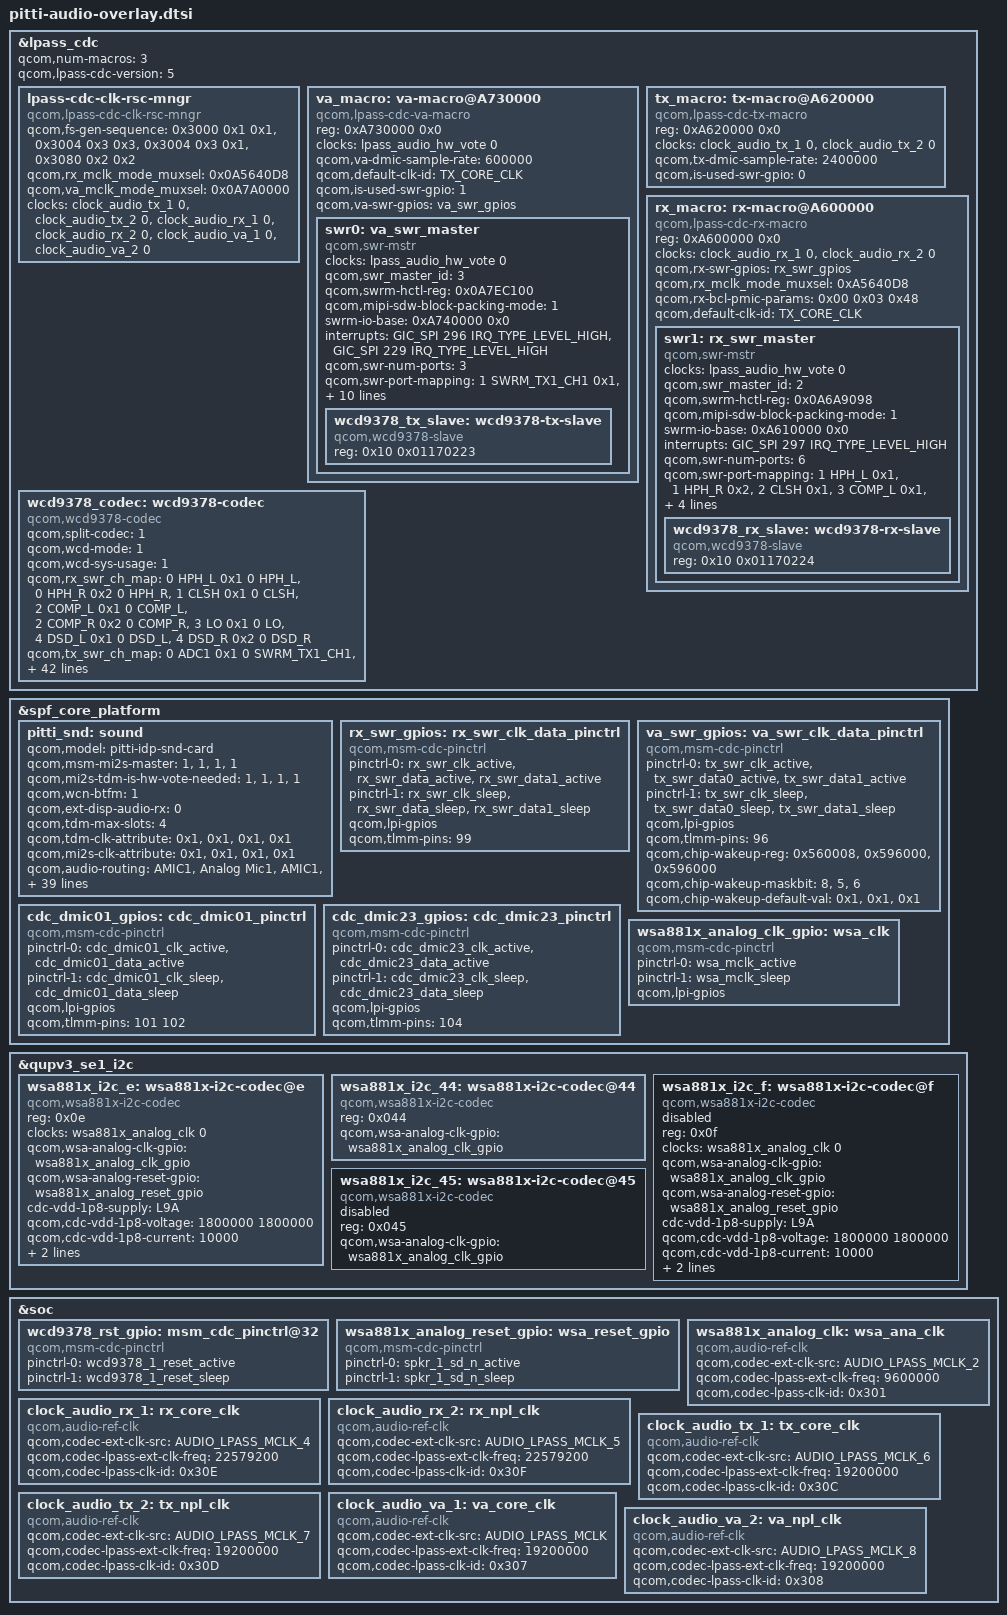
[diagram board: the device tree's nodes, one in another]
#include <bindings/qcom,audio-ext-clk.h>
#include <bindings/qcom,lpass-cdc-clk-rsc.h>
#include <bindings/audio-codec-port-types.h>
#include <dt-bindings/interrupt-controller/arm-gic.h>
#include <dt-bindings/gpio/gpio.h>
#include "pitti-lpi.dtsi"

&lpass_cdc {
	qcom,num-macros = <3>;
	qcom,lpass-cdc-version = <5>;
	#address-cells = <1>;
	#size-cells = <1>;
	lpass-cdc-clk-rsc-mngr {
		compatible = "qcom,lpass-cdc-clk-rsc-mngr";
		qcom,fs-gen-sequence = <0x3000 0x1 0x1>, <0x3004 0x3 0x3>,
					<0x3004 0x3 0x1>, <0x3080 0x2 0x2>;
	qcom,rx_mclk_mode_muxsel = <0x0A5640D8>;
	qcom,va_mclk_mode_muxsel = <0x0A7A0000>;
	clock-names = "tx_core_clk", "tx_npl_clk", "rx_core_clk", "rx_npl_clk",
		 "va_core_clk", "va_npl_clk";
	clocks = <&clock_audio_tx_1 0>, <&clock_audio_tx_2 0>,
		<&clock_audio_rx_1 0>, <&clock_audio_rx_2 0>,
		<&clock_audio_va_1 0>, <&clock_audio_va_2 0>;
	};

	va_macro: va-macro@A730000 {
		compatible = "qcom,lpass-cdc-va-macro";
		reg = <0xA730000 0x0>;
		clock-names = "lpass_audio_hw_vote";
		clocks = <&lpass_audio_hw_vote 0>;
		qcom,va-dmic-sample-rate = <600000>;
		qcom,default-clk-id = <TX_CORE_CLK>;
		qcom,is-used-swr-gpio = <1>;
		qcom,va-swr-gpios = <&va_swr_gpios>;
		swr0: va_swr_master {
			compatible = "qcom,swr-mstr";
			#address-cells = <2>;
			#size-cells = <0>;
			clock-names = "lpass_audio_hw_vote";
			clocks = <&lpass_audio_hw_vote 0>;
			qcom,swr_master_id = <3>;
			qcom,swrm-hctl-reg = <0x0A7EC100>;
			qcom,mipi-sdw-block-packing-mode = <1>;
			swrm-io-base = <0xA740000 0x0>;
			interrupts =
				<GIC_SPI 296 IRQ_TYPE_LEVEL_HIGH>,
				<GIC_SPI 229 IRQ_TYPE_LEVEL_HIGH>;
			interrupt-names = "swr_master_irq", "swr_wake_irq";
			qcom,swr-num-ports = <3>;
			qcom,swr-port-mapping = <1 SWRM_TX1_CH1 0x1>,
				<1 SWRM_TX1_CH2 0x2>,
				<1 SWRM_TX1_CH3 0x4>, <1 SWRM_TX1_CH4 0x8>,
				<2 SWRM_TX2_CH1 0x1>, <2 SWRM_TX2_CH2 0x2>,
				<2 SWRM_TX2_CH3 0x4>, <2 SWRM_TX2_CH4 0x8>,
				<3 SWRM_TX3_CH1 0x1>, <3 SWRM_TX3_CH2 0x2>,
				<3 SWRM_TX3_CH3 0x4>, <3 SWRM_TX3_CH4 0x8>;
			qcom,swr-num-dev = <1>;
			qcom,swr-clock-stop-mode0 = <1>;
			qcom,swr-mstr-irq-wakeup-capable = <1>;
			qcom,is-always-on = <1>;
			wcd9378_tx_slave: wcd9378-tx-slave {
				compatible = "qcom,wcd9378-slave";
				reg = <0x10 0x01170223>;
			};

		};
	};

	tx_macro: tx-macro@A620000 {
		compatible = "qcom,lpass-cdc-tx-macro";
		reg = <0xA620000 0x0>;
		clock-names = "tx_core_clk", "tx_npl_clk";
		clocks = <&clock_audio_tx_1 0>,
			 <&clock_audio_tx_2 0>;
		qcom,tx-dmic-sample-rate = <2400000>;
		qcom,is-used-swr-gpio = <0>;
	};

	rx_macro: rx-macro@A600000 {
		compatible = "qcom,lpass-cdc-rx-macro";
		reg = <0xA600000 0x0>;
		clock-names = "rx_core_clk", "rx_npl_clk";
		clocks = <&clock_audio_rx_1 0>,
			 <&clock_audio_rx_2 0>;
		qcom,rx-swr-gpios = <&rx_swr_gpios>;
		qcom,rx_mclk_mode_muxsel = <0xA5640D8>;
		qcom,rx-bcl-pmic-params = /bits/ 8 <0x00 0x03 0x48>;
		qcom,default-clk-id = <TX_CORE_CLK>;
		swr1: rx_swr_master {
			compatible = "qcom,swr-mstr";
			#address-cells = <2>;
			#size-cells = <0>;
			clock-names = "lpass_audio_hw_vote";
			clocks = <&lpass_audio_hw_vote 0>;
			qcom,swr_master_id = <2>;
			qcom,swrm-hctl-reg = <0x0A6A9098>;
			qcom,mipi-sdw-block-packing-mode = <1>;
			swrm-io-base = <0xA610000 0x0>;
			interrupts = <GIC_SPI 297 IRQ_TYPE_LEVEL_HIGH>;
			interrupt-names = "swr_master_irq";
			qcom,swr-num-ports = <6>;
			qcom,swr-port-mapping = <1 HPH_L 0x1>,
				<1 HPH_R 0x2>, <2 CLSH 0x1>,
				<3 COMP_L 0x1>, <3 COMP_R 0x2>,
				<4 LO 0x1>, <5 DSD_L 0x1>,
				<5 DSD_R 0x2>, <6 PCM_OUT1 0x01>;
			qcom,swr-num-dev = <1>;
			qcom,swr-clock-stop-mode0 = <1>;
			wcd9378_rx_slave: wcd9378-rx-slave {
				status = "okay";
				compatible = "qcom,wcd9378-slave";
				reg = <0x10 0x01170224>;
			};
		};
	};


	wcd9378_codec: wcd9378-codec {
		compatible = "qcom,wcd9378-codec";
		qcom,split-codec = <1>;
		qcom,wcd-mode = <1>;
		qcom,wcd-sys-usage = <1>;
		qcom,rx_swr_ch_map = <0 HPH_L 0x1 0 HPH_L>,
			<0 HPH_R 0x2 0 HPH_R>, <1 CLSH 0x1 0 CLSH>,
			<2 COMP_L 0x1 0 COMP_L>, <2 COMP_R 0x2 0 COMP_R>,
			<3 LO 0x1 0 LO>, <4 DSD_L 0x1 0 DSD_L>,
			<4 DSD_R 0x2 0 DSD_R>;

		qcom,tx_swr_ch_map = <0 ADC1 0x1 0 SWRM_TX1_CH1>,
			<1 ADC2 0x1 0 SWRM_TX1_CH2>,
			<2 ADC3 0x1 0 SWRM_TX1_CH3>,
			<3 DMIC0 0x4 0 SWRM_TX2_CH1>,
			<3 DMIC1 0x8 0 SWRM_TX2_CH2>,
			<3 MBHC 0x1 0 SWRM_TX2_CH3>,
			<4 DMIC2 0x1 0 SWRM_TX2_CH3>,
			<4 DMIC3 0x2 0 SWRM_TX2_CH4>,
			<4 DMIC4 0x3 0 SWRM_TX3_CH1>,
			<4 DMIC5 0x4 0 SWRM_TX3_CH2>;

		qcom,swr-tx-port-params =
			<OFFSET1_VAL1 LANE0>, <OFFSET1_VAL0 LANE1>, <OFFSET1_VAL0 LANE1>, <OFFSET1_VAL1 LANE0>,
			<OFFSET1_VAL0 LANE1>, <OFFSET1_VAL1 LANE0>, <OFFSET1_VAL1 LANE0>, <OFFSET1_VAL1 LANE0>,
			<OFFSET1_VAL0 LANE1>, <OFFSET1_VAL2 LANE0>, <OFFSET1_VAL1 LANE0>, <OFFSET1_VAL2 LANE0>,
			<OFFSET1_VAL1 LANE0>, <OFFSET1_VAL1 LANE0>, <OFFSET1_VAL1 LANE0>, <OFFSET1_VAL1 LANE0>;

		qcom,wcd-rst-gpio-node = <&wcd9378_rst_gpio>;
		qcom,rx-slave = <&wcd9378_rx_slave>;
		qcom,tx-slave = <&wcd9378_tx_slave>;

		cdc-vdd-rxtx-supply = <&L9A>;
		qcom,cdc-vdd-rxtx-voltage = <1800000 1800000>;
		qcom,cdc-vdd-rxtx-current = <30000>;
		qcom,cdc-vdd-rxtx-lpm-supported = <1>;

		cdc-vdd-io-supply = <&L9A>;
		qcom,cdc-vdd-io-voltage = <1800000 1800000>;
		qcom,cdc-vdd-io-current = <20000>;
		qcom,cdc-vdd-io-lpm-supported = <1>;

		cdc-vdd-buck-supply = <&L14A>;
		qcom,cdc-vdd-buck-voltage = <1800000 1800000>;
		qcom,cdc-vdd-buck-current = <650000>;
		qcom,cdc-vdd-buck-lpm-supported = <1>;

		cdc-vdd-mic-bias-supply = <>;
		qcom,cdc-vdd-mic-bias-voltage = <3296000 3296000>;
		qcom,cdc-vdd-mic-bias-current = <405400>;

		qcom,cdc-micbias1-mv = <1800>;
		qcom,cdc-micbias2-mv = <1800>;
		qcom,cdc-micbias3-mv = <1800>;

		qcom,cdc-static-supplies = "cdc-vdd-rxtx",
					   "cdc-vdd-io";
		qcom,cdc-on-demand-supplies = "cdc-vdd-buck";
	};

};

&spf_core_platform  {
	pitti_snd: sound {
		qcom,model = "pitti-idp-snd-card";
		qcom,msm-mi2s-master = <1>, <1>, <1>, <1>;
		qcom,mi2s-tdm-is-hw-vote-needed = <1>, <1>, <1>, <1>;
		qcom,wcn-btfm = <1>;
		qcom,ext-disp-audio-rx = <0>;
		qcom,tdm-max-slots = <4>;
		qcom,tdm-clk-attribute = <0x1>, <0x1>, <0x1>, <0x1>;
		qcom,mi2s-clk-attribute = <0x1>, <0x1>, <0x1>, <0x1>;
		qcom,audio-routing =
			"AMIC1", "Analog Mic1",
			"AMIC1", "MIC BIAS1",
			"AMIC2", "Analog Mic2",
			"AMIC2", "MIC BIAS2",
			"AMIC3", "Analog Mic3",
			"AMIC3", "MIC BIAS3",
			"VA AMIC1", "Analog Mic1",
			"VA AMIC1", "VA MIC BIAS1",
			"VA AMIC2", "Analog Mic2",
			"VA AMIC2", "VA MIC BIAS2",
			"VA AMIC3", "Analog Mic3",
			"VA AMIC3", "VA MIC BIAS3",
			"TX DMIC0", "Digital Mic0",
			"TX DMIC0", "MIC BIAS3",
			"TX DMIC1", "Digital Mic1",
			"TX DMIC1", "MIC BIAS3",
			"TX DMIC2", "Digital Mic2",
			"TX DMIC2", "MIC BIAS1",
			"TX DMIC3", "Digital Mic3",
			"TX DMIC3", "MIC BIAS1",
			"IN1_HPHL", "HPHL_OUT",
			"IN2_HPHR", "HPHR_OUT",
			"IN3_AUX", "AUX_OUT",
			"RX_TX DEC0_INP", "TX DEC0 MUX",
			"RX_TX DEC1_INP", "TX DEC1 MUX",
			"RX_TX DEC2_INP", "TX DEC2 MUX",
			"RX_TX DEC3_INP", "TX DEC3 MUX",
			"SpkrMono WSA_IN", "AUX",
			"TX SWR_INPUT", "ADC1_OUTPUT",
			"TX SWR_INPUT", "ADC2_OUTPUT",
			"TX SWR_INPUT", "ADC3_OUTPUT",
			"VA SWR_INPUT", "VA_SWR_CLK",
			"VA SWR_INPUT", "ADC1_OUTPUT",
			"VA SWR_INPUT", "ADC2_OUTPUT",
			"VA SWR_INPUT", "ADC3_OUTPUT",
			"VA_AIF1 CAP", "VA_SWR_CLK",
			"VA_AIF2 CAP", "VA_SWR_CLK",
			"VA_AIF3 CAP", "VA_SWR_CLK",
			"VA DMIC0", "Digital Mic0",
			"VA DMIC0", "VA MIC BIAS3",
			"VA DMIC1", "Digital Mic1",
			"VA DMIC1", "VA MIC BIAS3",
			"VA DMIC2", "Digital Mic2",
			"VA DMIC2", "VA MIC BIAS1",
			"VA DMIC3", "Digital Mic3",
			"VA DMIC3", "VA MIC BIAS1";
		qcom,msm-mbhc-usbc-audio-supported = <0>;
		qcom,msm-mbhc-hphl-swh = <1>;
		qcom,msm-mbhc-gnd-swh = <1>;
		qcom,cdc-dmic01-gpios = <&cdc_dmic01_gpios>;
		qcom,cdc-dmic23-gpios = <&cdc_dmic23_gpios>;

		asoc-codec  = <&stub_codec>, <&lpass_cdc>,
				  <&wcd9378_codec>, <&wsa881x_i2c_e>;
		asoc-codec-names = "msm-stub-codec.1", "lpass-cdc",
				   "wcd9378_codec", "wsa-codec0";
		qcom,wsa-aux-dev-prefix = "SpkrMono";
		qcom,msm_audio_ssr_devs = <&audio_gpr>, <&lpi_tlmm>,
									<&lpass_cdc>;
	};

	rx_swr_gpios: rx_swr_clk_data_pinctrl {
		compatible = "qcom,msm-cdc-pinctrl";
		pinctrl-names = "aud_active", "aud_sleep";
		pinctrl-0 = <&rx_swr_clk_active &rx_swr_data_active
				&rx_swr_data1_active>;
		pinctrl-1 = <&rx_swr_clk_sleep &rx_swr_data_sleep
				&rx_swr_data1_sleep>;
		qcom,lpi-gpios;
		qcom,tlmm-pins = <99>;
		#gpio-cells = <0>;
	};

	va_swr_gpios: va_swr_clk_data_pinctrl {
		compatible = "qcom,msm-cdc-pinctrl";
		pinctrl-names = "aud_active", "aud_sleep";
		pinctrl-0 = <&tx_swr_clk_active &tx_swr_data0_active
			    &tx_swr_data1_active>;
		pinctrl-1 = <&tx_swr_clk_sleep &tx_swr_data0_sleep
			    &tx_swr_data1_sleep>;
		qcom,lpi-gpios;
		qcom,tlmm-pins = <96>;
		qcom,chip-wakeup-reg = <0x560008>, <0x596000>, <0x596000>;
		qcom,chip-wakeup-maskbit = <8>, <5>, <6>;
		qcom,chip-wakeup-default-val = <0x1>, <0x1>, <0x1>;
		#gpio-cells = <0>;
	};

	cdc_dmic01_gpios: cdc_dmic01_pinctrl {
		compatible = "qcom,msm-cdc-pinctrl";
		pinctrl-names = "aud_active", "aud_sleep";
		pinctrl-0 = <&cdc_dmic01_clk_active &cdc_dmic01_data_active>;
		pinctrl-1 = <&cdc_dmic01_clk_sleep &cdc_dmic01_data_sleep>;
		qcom,lpi-gpios;
		qcom,tlmm-pins = <101 102>;
		#gpio-cells = <0>;
	};

	cdc_dmic23_gpios: cdc_dmic23_pinctrl {
		compatible = "qcom,msm-cdc-pinctrl";
		pinctrl-names = "aud_active", "aud_sleep";
		pinctrl-0 = <&cdc_dmic23_clk_active &cdc_dmic23_data_active>;
		pinctrl-1 = <&cdc_dmic23_clk_sleep &cdc_dmic23_data_sleep>;
		qcom,lpi-gpios;
		qcom,tlmm-pins = <104>;
		#gpio-cells = <0>;
	};

	wsa881x_analog_clk_gpio: wsa_clk {
		compatible = "qcom,msm-cdc-pinctrl";
		pinctrl-names = "aud_active", "aud_sleep";
		pinctrl-0 = <&wsa_mclk_active>;
		pinctrl-1 = <&wsa_mclk_sleep>;
		qcom,lpi-gpios;
		#gpio-cells = <0>;
	};

};

&qupv3_se1_i2c {
	wsa881x_i2c_e: wsa881x-i2c-codec@e {
		compatible = "qcom,wsa881x-i2c-codec";
		reg = <0x0e>;
		clock-names = "wsa_mclk";
		clocks = <&wsa881x_analog_clk 0>;
		qcom,wsa-analog-clk-gpio = <&wsa881x_analog_clk_gpio>;
		qcom,wsa-analog-reset-gpio = <&wsa881x_analog_reset_gpio>;
		cdc-vdd-1p8-supply = <&L9A>;
		qcom,cdc-vdd-1p8-voltage = <1800000 1800000>;
		qcom,cdc-vdd-1p8-current = <10000>;
		qcom,cdc-static-supplies = "cdc-vdd-1p8";
		qcom,wsa-prefix = "SpkrMono";
	};

	wsa881x_i2c_44: wsa881x-i2c-codec@44 {
		compatible = "qcom,wsa881x-i2c-codec";
		reg = <0x044>;
		qcom,wsa-analog-clk-gpio = <&wsa881x_analog_clk_gpio>;
	};

	wsa881x_i2c_f: wsa881x-i2c-codec@f {
		status = "disabled";
		compatible = "qcom,wsa881x-i2c-codec";
		reg = <0x0f>;
		clock-names = "wsa_mclk";
		clocks = <&wsa881x_analog_clk 0>;
		qcom,wsa-analog-clk-gpio = <&wsa881x_analog_clk_gpio>;
		qcom,wsa-analog-reset-gpio = <&wsa881x_analog_reset_gpio>;
		cdc-vdd-1p8-supply = <&L9A>;
		qcom,cdc-vdd-1p8-voltage = <1800000 1800000>;
		qcom,cdc-vdd-1p8-current = <10000>;
		qcom,cdc-static-supplies = "cdc-vdd-1p8";
		qcom,wsa-prefix = "SpkrMono";
	};

	wsa881x_i2c_45: wsa881x-i2c-codec@45 {
		status = "disabled";
		compatible = "qcom,wsa881x-i2c-codec";
		reg = <0x045>;
		qcom,wsa-analog-clk-gpio = <&wsa881x_analog_clk_gpio>;
	};
};

&soc {
	wcd9378_rst_gpio: msm_cdc_pinctrl@32 {
		compatible = "qcom,msm-cdc-pinctrl";
		pinctrl-names = "aud_active", "aud_sleep";
		pinctrl-0 = <&wcd9378_1_reset_active>;
		pinctrl-1 = <&wcd9378_1_reset_sleep>;
	};

	wsa881x_analog_reset_gpio: wsa_reset_gpio {
		compatible = "qcom,msm-cdc-pinctrl";
		pinctrl-names = "aud_active", "aud_sleep";
		pinctrl-0 = <&spkr_1_sd_n_active>;
		pinctrl-1 = <&spkr_1_sd_n_sleep>;
		#gpio-cells = <0>;
	};

	wsa881x_analog_clk: wsa_ana_clk {
		compatible = "qcom,audio-ref-clk";
		qcom,codec-ext-clk-src = <AUDIO_LPASS_MCLK_2>;
		qcom,codec-lpass-ext-clk-freq = <9600000>;
		qcom,codec-lpass-clk-id = <0x301>;
		#clock-cells = <1>;
	};

	clock_audio_rx_1: rx_core_clk {
		compatible = "qcom,audio-ref-clk";
		qcom,codec-ext-clk-src = <AUDIO_LPASS_MCLK_4>;
		qcom,codec-lpass-ext-clk-freq = <22579200>;
		qcom,codec-lpass-clk-id = <0x30E>;
		#clock-cells = <1>;
	};

	clock_audio_rx_2: rx_npl_clk {
		compatible = "qcom,audio-ref-clk";
		qcom,codec-ext-clk-src = <AUDIO_LPASS_MCLK_5>;
		qcom,codec-lpass-ext-clk-freq = <22579200>;
		qcom,codec-lpass-clk-id = <0x30F>;
		#clock-cells = <1>;
	};

	clock_audio_tx_1: tx_core_clk {
		compatible = "qcom,audio-ref-clk";
		qcom,codec-ext-clk-src = <AUDIO_LPASS_MCLK_6>;
		qcom,codec-lpass-ext-clk-freq = <19200000>;
		qcom,codec-lpass-clk-id = <0x30C>;
		#clock-cells = <1>;
	};

	clock_audio_tx_2: tx_npl_clk {
		compatible = "qcom,audio-ref-clk";
		qcom,codec-ext-clk-src = <AUDIO_LPASS_MCLK_7>;
		qcom,codec-lpass-ext-clk-freq = <19200000>;
		qcom,codec-lpass-clk-id = <0x30D>;
		#clock-cells = <1>;
	};

	clock_audio_va_1: va_core_clk {
		compatible = "qcom,audio-ref-clk";
		qcom,codec-ext-clk-src = <AUDIO_LPASS_MCLK>;
		qcom,codec-lpass-ext-clk-freq = <19200000>;
		qcom,codec-lpass-clk-id = <0x307>;
		#clock-cells = <1>;
	};

	clock_audio_va_2: va_npl_clk {
		compatible = "qcom,audio-ref-clk";
		qcom,codec-ext-clk-src = <AUDIO_LPASS_MCLK_8>;
		qcom,codec-lpass-ext-clk-freq = <19200000>;
		qcom,codec-lpass-clk-id = <0x308>;
		#clock-cells = <1>;
	};
};
